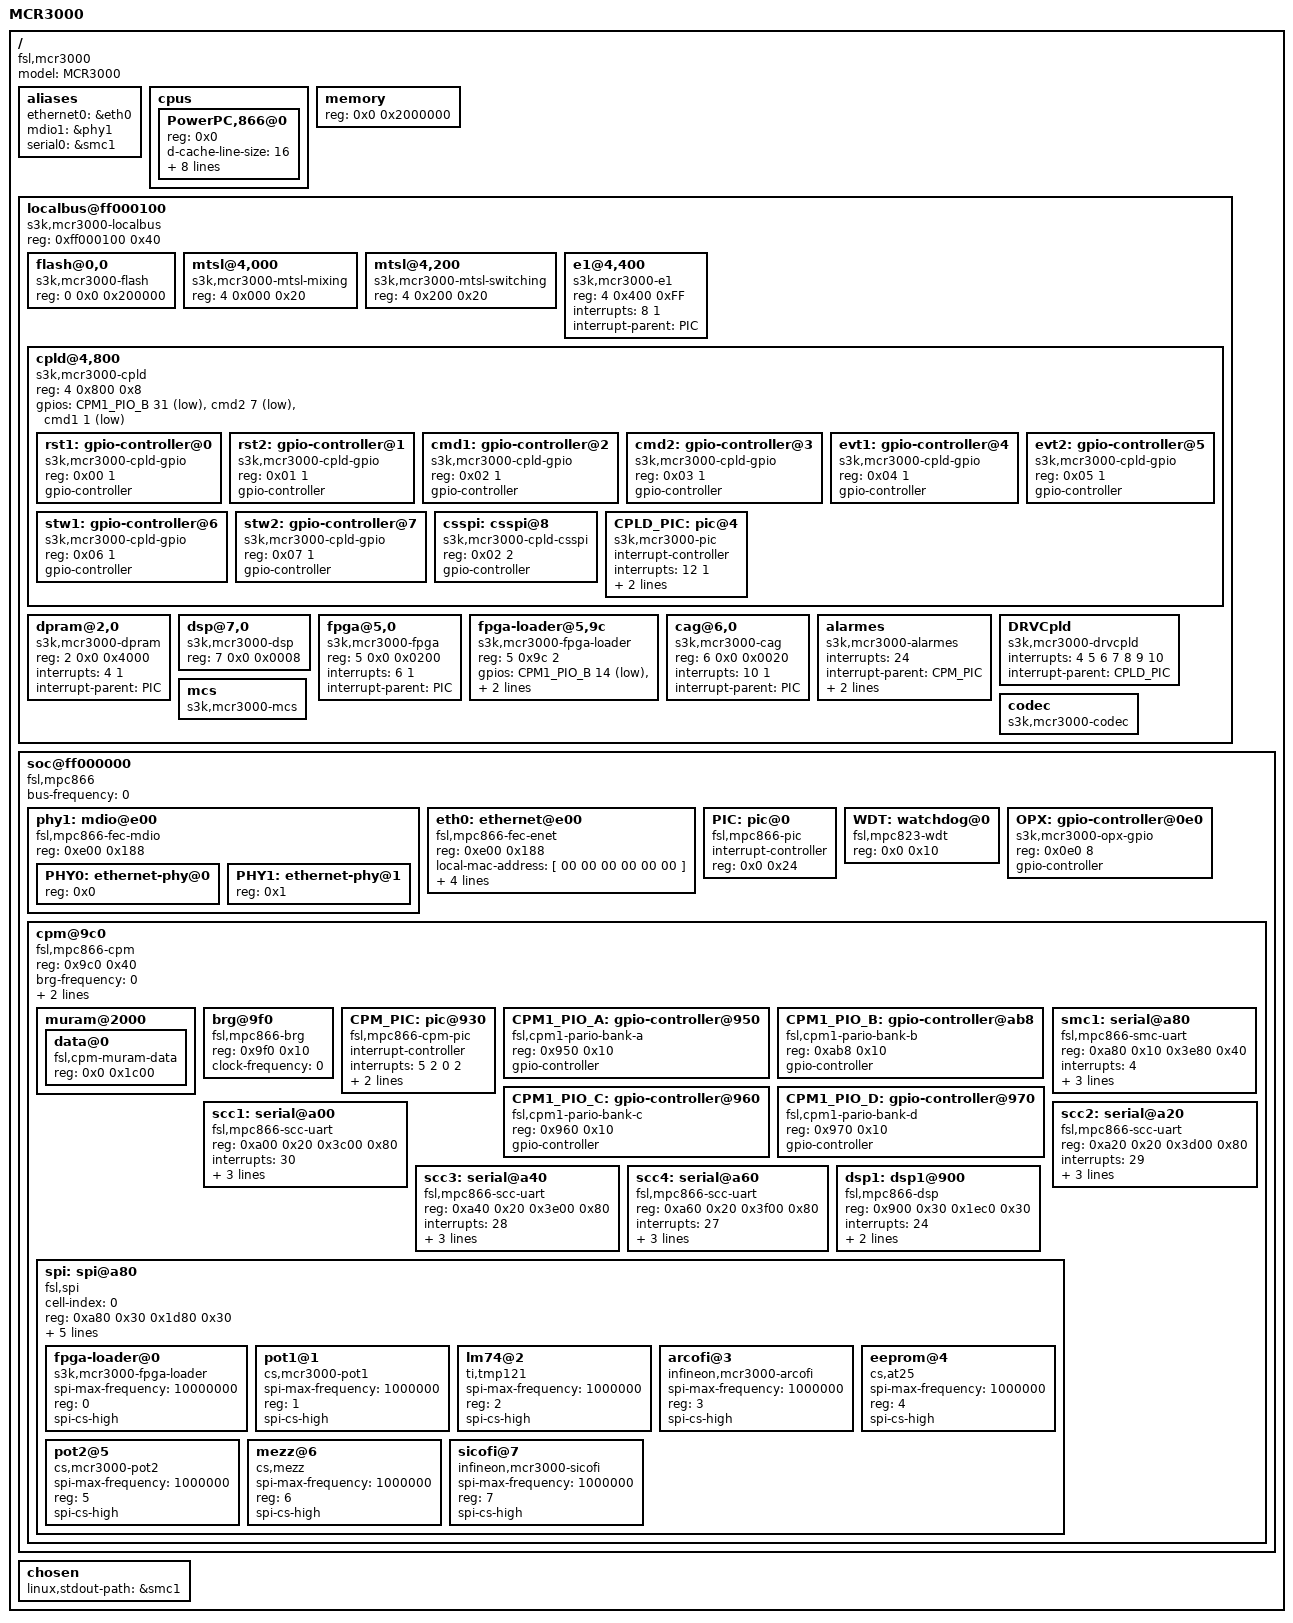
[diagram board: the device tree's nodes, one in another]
/*
 * MCR3000 Device Tree Source
 *
 * Copyright 2010 CSSI, Inc
 */

/dts-v1/;

/ {
	model = "MCR3000";
	compatible = "fsl,mcr3000";
	#address-cells = <1>;
	#size-cells = <1>;

	aliases {
		ethernet0 = &eth0;
		mdio1 = &phy1;
		serial0 = &smc1;
	};

	cpus {
		#address-cells = <1>;
		#size-cells = <0>;

		PowerPC,866@0 {
			device_type = "cpu";
			reg = <0x0>;
			d-cache-line-size = <16>;	// 16 bytes
			i-cache-line-size = <16>;	// 16 bytes
			d-cache-size = <0x2000>;	// L1, 8K
			i-cache-size = <0x4000>;	// L1, 16K
			timebase-frequency = <0>;
			bus-frequency = <0>;
			clock-frequency = <0>;
			interrupts = <15 2>;		// decrementer interrupt
			interrupt-parent = <&PIC>;
		};
	};

	memory {
		device_type = "memory";
		reg = <0x0 0x2000000>;			// memory at offset 0x00000000 and lenght 0x02000000
	};

	localbus@ff000100 {
		compatible = "s3k,mcr3000-localbus", "fsl,pq1-localbus";
		#address-cells = <2>;
		#size-cells = <1>;
		reg = <0xff000100 0x40>;		// ORx and BRx register


		ranges = <0x0 0 0x04000000 0x04000000 // BOOT
			  0x1 0 0x00000000 0x04000000 // SDRAM
			  0x2 0 0x08000000 0x04000000 // RAMDP
			  0x3 0 0x0C000000 0x04000000 // NAND
			  0x4 0 0x10000000 0x04000000 // Periphs
			  0x5 0 0x14000000 0x04000000 // FPGA
			  0x6 0 0x18000000 0x04000000 // mezzanine
			  0x7 0 0x1c000000 0x04000000>; // DSP
			  
		flash@0,0 {
			#address-cells = <1>;
			#size-cells = <1>;
			compatible = "s3k,mcr3000-flash";
			reg = <0 0x0 0x200000>;
		};
		
		mtsl@4,000 {
			#address-cells = <1>;
			#size-cells = <1>;
			compatible = "s3k,mcr3000-mtsl-mixing";
			reg = <4 0x000 0x20>;
		};
		
		mtsl@4,200 {
			#address-cells = <1>;
			#size-cells = <1>;
			compatible = "s3k,mcr3000-mtsl-switching";
			reg = <4 0x200 0x20>;
		};
		
		e1@4,400 {
			#address-cells = <1>;
			#size-cells = <1>;
			compatible = "s3k,mcr3000-e1";
			reg = <4 0x400 0xFF>;
			interrupts = <8 1>;
			interrupt-parent = <&PIC>;
		};

		cpld@4,800 {
			#address-cells = <1>;
			#size-cells = <1>;
			compatible = "s3k,mcr3000-cpld";
			reg = <4 0x800 0x8>;
			ranges = <0 4 0x800 0x8>;
			gpios = <&CPM1_PIO_B 31 1	// SPISEL
				&cmd2 7 1		// masque IRQ CPLD
				&cmd1 1 1>;		// validation ETH2
			
			rst1: gpio-controller@0 {
				#gpio-cells = <2>;
				compatible = "s3k,mcr3000-cpld-gpio";
				reg = <0x00 1>;
				gpio-controller;
			};
			rst2: gpio-controller@1 {
				#gpio-cells = <2>;
				compatible = "s3k,mcr3000-cpld-gpio";
				reg = <0x01 1>;
				gpio-controller;
			};
			cmd1: gpio-controller@2 {
				#gpio-cells = <2>;
				compatible = "s3k,mcr3000-cpld-gpio";
				reg = <0x02 1>;
				gpio-controller;
			};
			cmd2: gpio-controller@3 {
				#gpio-cells = <2>;
				compatible = "s3k,mcr3000-cpld-gpio";
				reg = <0x03 1>;
				gpio-controller;
			};
			evt1: gpio-controller@4 {
				#gpio-cells = <2>;
				compatible = "s3k,mcr3000-cpld-gpio";
				reg = <0x04 1>;
/*				interrupts = <6 1>;
				interrupt-parent = <&PIC>;*/
				gpio-controller;
			};
			evt2: gpio-controller@5 {
				#gpio-cells = <2>;
				compatible = "s3k,mcr3000-cpld-gpio";
				reg = <0x05 1>;
/*				interrupts = <6 1>;
				interrupt-parent = <&PIC>;*/
				gpio-controller;
			};
			stw1: gpio-controller@6 {
				#gpio-cells = <2>;
				compatible = "s3k,mcr3000-cpld-gpio";
				reg = <0x06 1>;
				gpio-controller;
			};
			stw2: gpio-controller@7 {
				#gpio-cells = <2>;
				compatible = "s3k,mcr3000-cpld-gpio";
				reg = <0x07 1>;
				gpio-controller;
			};
			
			csspi: csspi@8 {
				#gpio-cells = <2>;
				compatible = "s3k,mcr3000-cpld-csspi";
				reg = <0x02 2>;
				gpio-controller;
			};
			
			CPLD_PIC: pic@4 {
				interrupt-controller;
				#address-cells = <0>;
				#interrupt-cells = <1>;
				interrupts = <12 1>;
				interrupt-parent = <&PIC>;
				reg = <0x4 2>;
				compatible = "s3k,mcr3000-pic";
			};
		};
		dpram@2,0 {
			#address-cells = <1>;
			#size-cells = <1>;
			compatible = "s3k,mcr3000-dpram";
			reg = <2 0x0 0x4000>;
			interrupts = <4 1>;
			interrupt-parent = <&PIC>;
		};
		dsp@7,0 {
			#address-cells = <1>;
			#size-cells = <1>;
			compatible = "s3k,mcr3000-dsp";
			reg = <7 0x0 0x0008>;
		};
		fpga@5,0 {
			#address-cells = <1>;
			#size-cells = <1>;
			compatible = "s3k,mcr3000-fpga";
			reg = <5 0x0 0x0200>;
			interrupts = <6 1>;
			interrupt-parent = <&PIC>;
		};
		fpga-loader@5,9c {
			#address-cells = <1>;
			#size-cells = <1>;
			compatible = "s3k,mcr3000-fpga-loader";
			reg = <5 0x9c 2>; /* Register RIDENT */
			gpios = <&CPM1_PIO_B 14 1	// PROGFPGA\
				&CPM1_PIO_B 16 1	// INITFPGA\
				&CPM1_PIO_B 17 1	// DONEFPGA\
				&rst2 1 1 >;		// RST_FPGA\
		};
		cag@6,0 {
			#address-cells = <1>;
			#size-cells = <1>;
			compatible = "s3k,mcr3000-cag";
			reg = <6 0x0 0x0020>;
			interrupts = <10 1>;
			interrupt-parent = <&PIC>;
		};
		alarmes {
			compatible = "s3k,mcr3000-alarmes";
			interrupts = <24>;
			interrupt-parent = <&CPM_PIC>;
			gpios = <&CPM1_PIO_C 13 1 	// ACQ_ALRM
				&OPX 1 1		// ALRM_MAJ
				&CPM1_PIO_D 15 1>;	// ALRM_MIN
		};
		DRVCpld {
			compatible = "s3k,mcr3000-drvcpld";
			interrupts = <4 5 6 7 8 9 10>;
			interrupt-parent = <&CPLD_PIC>;
		};
		codec {
			compatible = "s3k,mcr3000-codec";
		};
		mcs {
			compatible = "s3k,mcr3000-mcs";
		};
	};

	soc@ff000000 {
		compatible = "fsl,mpc866", "fsl,pq1-soc";
		#address-cells = <1>;
		#size-cells = <1>;
		device_type = "soc";
		ranges = <0x0 0xff000000 0x4000>;
		bus-frequency = <0>;

		phy1: mdio@e00 {
			compatible = "fsl,mpc866-fec-mdio", "fsl,pq1-fec-mdio";
			reg = <0xe00 0x188>;
			#address-cells = <1>;
			#size-cells = <0>;
			PHY0: ethernet-phy@0 {
				reg = <0x0>;
				device_type = "ethernet-phy";
			};
			PHY1: ethernet-phy@1 {
				reg = <0x1>;
				device_type = "ethernet-phy";
			};
		};

		eth0: ethernet@e00 {
			device_type = "network";
			compatible = "fsl,mpc866-fec-enet", "fsl,pq1-fec-enet";
			reg = <0xe00 0x188>;
			local-mac-address = [ 00 00 00 00 00 00 ];
			interrupts = <3 1>;
			interrupt-parent = <&PIC>;
			phy-handle = <&PHY0 &PHY1>;
			linux,network-index = <0>;
		};

		PIC: pic@0 {
			interrupt-controller;
			#interrupt-cells = <2>;
			reg = <0x0 0x24>;
			compatible = "fsl,mpc866-pic", "fsl,pq1-pic";
		};
		
		WDT: watchdog@0 {
			compatible = "fsl,mpc823-wdt";
			reg = <0x0 0x10>;
		};
		
		OPX: gpio-controller@0e0{
			#gpio-cells = <2>;
			compatible = "s3k,mcr3000-opx-gpio";
			reg = <0x0e0 8>;
			gpio-controller;
		};

		cpm@9c0 {
			#address-cells = <1>;
			#size-cells = <1>;
			compatible = "fsl,mpc866-cpm", "fsl,cpm1";
			ranges;
			reg = <0x9c0 0x40>;
			brg-frequency = <0>;
			interrupts = <0>;	// cpm error interrupt
			interrupt-parent = <&CPM_PIC>;

			muram@2000 {
				#address-cells = <1>;
				#size-cells = <1>;
				ranges = <0x0 0x2000 0x2000>;

				data@0 {
					compatible = "fsl,cpm-muram-data";
					reg = <0x0 0x1c00>; // pas correct, devrait etre 0x1c00 mais pb driver spi
				};
			};

			brg@9f0 {
				compatible = "fsl,mpc866-brg", "fsl,cpm1-brg", "fsl,cpm-brg";
				reg = <0x9f0 0x10>;
				clock-frequency = <0>;
			};

			CPM_PIC: pic@930 {
				interrupt-controller;
				#address-cells = <0>;
				#interrupt-cells = <1>;
				interrupts = <5 2 0 2>;
				interrupt-parent = <&PIC>;
				reg = <0x930 0x20>;
				compatible = "fsl,mpc866-cpm-pic", "fsl,cpm1-pic";
			};

			CPM1_PIO_A: gpio-controller@950 {
				#gpio-cells = <2>;
				compatible = "fsl,cpm1-pario-bank-a";
				reg = <0x950 0x10>;
				gpio-controller;
			};
		
			CPM1_PIO_B: gpio-controller@ab8 {
				#gpio-cells = <2>;
				compatible = "fsl,cpm1-pario-bank-b";
				reg = <0xab8 0x10>;
				gpio-controller;
			};
		
			CPM1_PIO_C: gpio-controller@960 {
				#gpio-cells = <2>;
				compatible = "fsl,cpm1-pario-bank-c";
				reg = <0x960 0x10>;
				gpio-controller;
			};
		
			CPM1_PIO_D: gpio-controller@970 {
				#gpio-cells = <2>;
				compatible = "fsl,cpm1-pario-bank-d";
				reg = <0x970 0x10>;
				gpio-controller;
			};
		
			smc1: serial@a80 {
				device_type = "serial";
				compatible = "fsl,mpc866-smc-uart", "fsl,cpm1-smc-uart";
				reg = <0xa80 0x10 0x3e80 0x40>;
				interrupts = <4>;
				interrupt-parent = <&CPM_PIC>;
				fsl,cpm-brg = <1>;
				fsl,cpm-command = <0x90>;
			};

			scc1: serial@a00 {
				device_type = "serial";
				compatible = "fsl,mpc866-scc-uart", "fsl,cpm1-scc-uart";
				reg = <0xa00 0x20 0x3c00 0x80>;
				interrupts = <30>;
				interrupt-parent = <&CPM_PIC>;
				fsl,cpm-brg = <2>;
				fsl,cpm-command = <0x00>;
			};

			scc2: serial@a20 {
				device_type = "serial";
				compatible = "fsl,mpc866-scc-uart", "fsl,cpm1-scc-uart";
				reg = <0xa20 0x20 0x3d00 0x80>;
				interrupts = <29>;
				interrupt-parent = <&CPM_PIC>;
				fsl,cpm-brg = <3>;
				fsl,cpm-command = <0x40>;
			};

			scc3: serial@a40 {
				device_type = "serial";
				compatible = "fsl,mpc866-scc-uart", "fsl,cpm1-scc-uart";
				reg = <0xa40 0x20 0x3e00 0x80>;
				interrupts = <28>;
				interrupt-parent = <&CPM_PIC>;
				fsl,cpm-brg = <4>;
				fsl,cpm-command = <0x80>;
			};

			scc4: serial@a60 {
				device_type = "serial";
				compatible = "fsl,mpc866-scc-uart", "fsl,cpm1-scc-uart";
				reg = <0xa60 0x20 0x3f00 0x80>;
				interrupts = <27>;
				interrupt-parent = <&CPM_PIC>;
				fsl,cpm-brg = <4>;
				fsl,cpm-command = <0xc0>;
			};

			dsp1: dsp1@900 {
				compatible = "fsl,mpc866-dsp", "fsl,cpm1-dsp";
				reg = <0x900 0x30 0x1ec0 0x30>;
				interrupts = <24>;
				interrupt-parent = <&CPM_PIC>;
				fsl,cpm-command = <0x00>;
			};

			spi: spi@a80 {
				#address-cells = <1>;
				#size-cells = <0>;
				cell-index = <0>;
				compatible = "fsl,spi", "fsl,cpm1-spi";
				reg = <0xa80 0x30 0x1d80 0x30>;
				interrupts = <5>;
				interrupt-parent = <&CPM_PIC>;
				mode = "cpu";
				gpios = <&csspi 0 0	// device reg=<0> /* FPGA */
					 &csspi 1 0	// device reg=<1> /* POT1 */
					 &csspi 2 0	// device reg=<2> /* TEMP */
					 &csspi 3 0	// device reg=<3> /* ARCOFI */
					 &csspi 4 0	// device reg=<4> /* EEPROM */
					 &csspi 5 0	// device reg=<5> /* POT2 */
					 &csspi 6 0	// device reg=<6> /* MEZZ */
					 &csspi 7 0>;	// device reg=<7> /* SICOFI */
					 
				fpga-loader@0 {
					compatible = "s3k,mcr3000-fpga-loader";
					spi-max-frequency = <10000000>;
					reg = <0>;
					spi-cs-high;
				};
				pot1@1 {
					compatible = "cs,mcr3000-pot1";
					spi-max-frequency = <1000000>;
					reg = <1>;
					spi-cs-high;
				};
				lm74@2 {
					compatible = "ti,tmp121", "ns,lm74";
					spi-max-frequency = <1000000>;
					reg = <2>;
					spi-cs-high;
				};
				arcofi@3 {
					compatible = "infineon,mcr3000-arcofi";
					spi-max-frequency = <1000000>;
					reg = <3>;
					spi-cs-high;
				};
				eeprom@4 {
					compatible = "cs,at25", "cs,eeprom";
					spi-max-frequency = <1000000>;
					reg = <4>;
					spi-cs-high;
				};
				pot2@5 {
					compatible = "cs,mcr3000-pot2";
					spi-max-frequency = <1000000>;
					reg = <5>;
					spi-cs-high;
				};
				mezz@6 {
					compatible = "cs,mezz";
					spi-max-frequency = <1000000>;
					reg = <6>;
					spi-cs-high;
				};
				sicofi@7 {
					compatible = "infineon,mcr3000-sicofi";
					spi-max-frequency = <1000000>;
					reg = <7>;
					spi-cs-high;
				};
				
			};
			
		};
	};

	chosen {
		linux,stdout-path = &smc1;
	};
};
